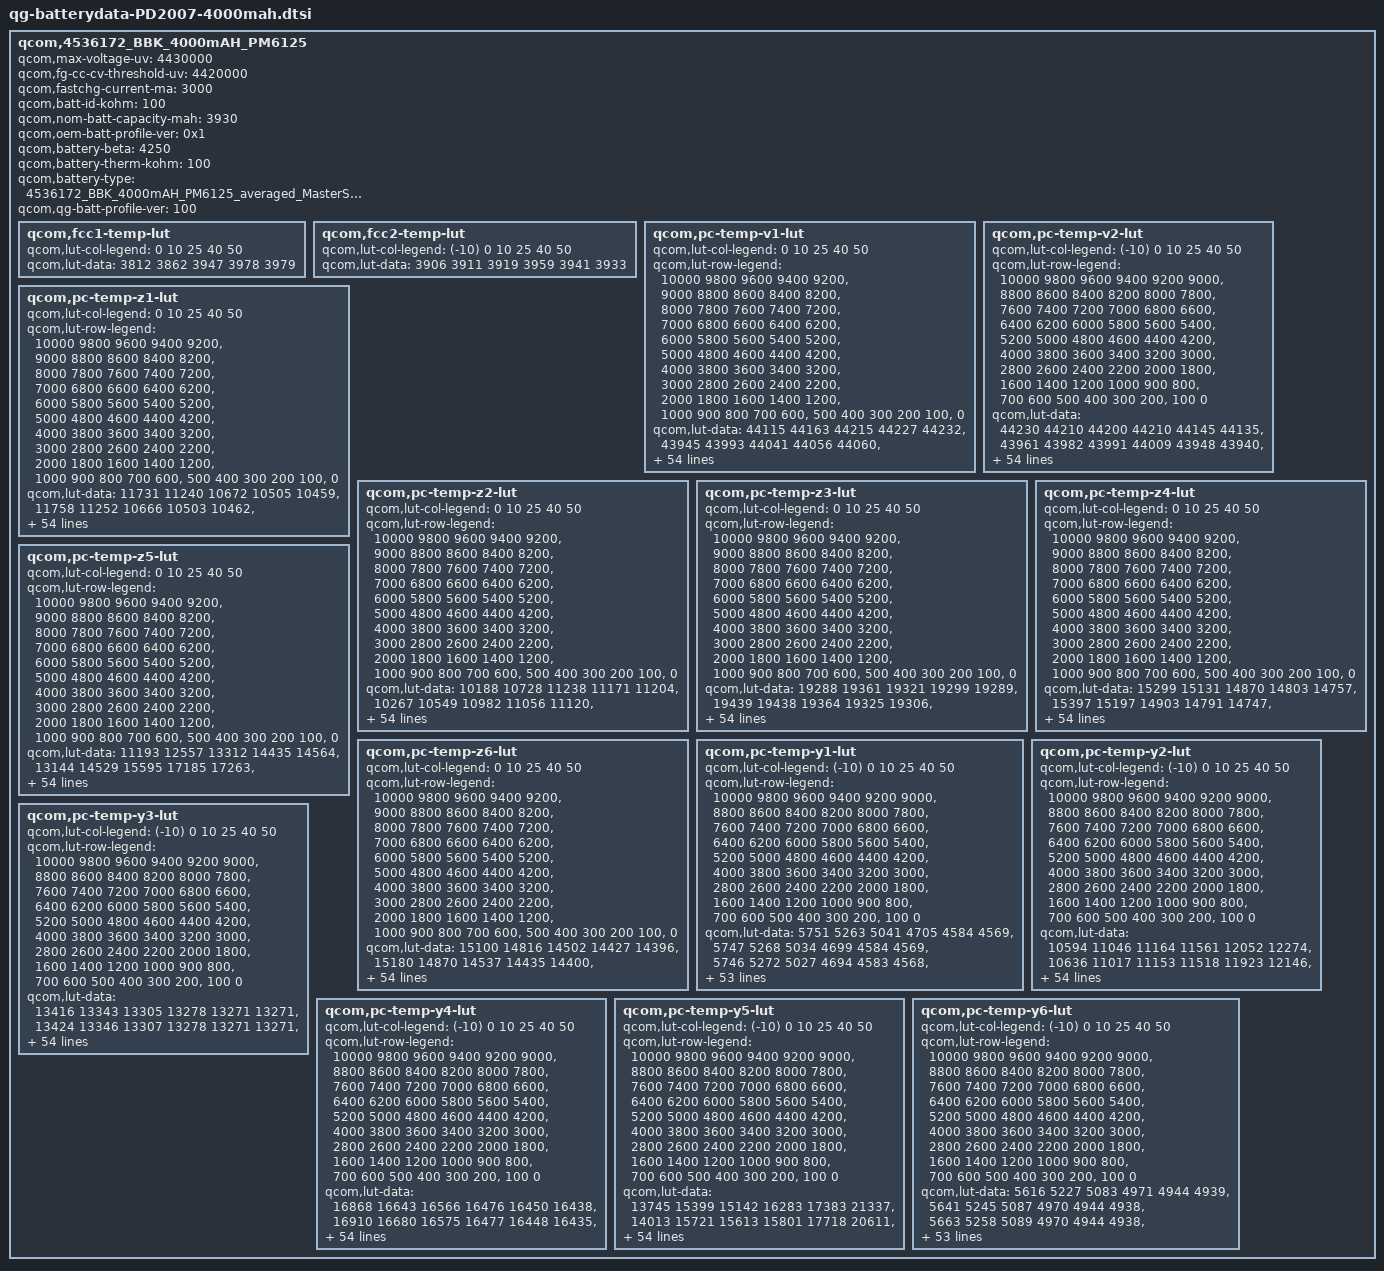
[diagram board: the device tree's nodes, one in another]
qcom,4536172_BBK_4000mAH_PM6125 {
    /* 4536172_BBK_4000mAH_PM6125_averaged_MasterSlave_Apr3th2020 */
    qcom,max-voltage-uv = <4430000>;
    qcom,fg-cc-cv-threshold-uv = <4420000>;
    qcom,fastchg-current-ma = <3000>;
    qcom,batt-id-kohm = <100>;
    qcom,nom-batt-capacity-mah = <3930>;/*min value*/
    qcom,oem-batt-profile-ver = <0x1>;
    qcom,battery-beta = <4250>;
    qcom,battery-therm-kohm = <100>;
    qcom,battery-type = "4536172_BBK_4000mAH_PM6125_averaged_MasterSlave_Apr3th2020";
    qcom,qg-batt-profile-ver = <100>;

	qcom,fcc1-temp-lut {
		qcom,lut-col-legend = <0 10 25 40 50>;
		qcom,lut-data = <3812 3862 3947 3978 3979>;
	};

	qcom,fcc2-temp-lut {
		qcom,lut-col-legend = <(-10) 0 10 25 40 50>;
		qcom,lut-data = <3906 3911 3919 3959 3941 3933>;
	};

	qcom,pc-temp-v1-lut {
		qcom,lut-col-legend = <0 10 25 40 50>;
		qcom,lut-row-legend = <10000 9800 9600 9400 9200>,
			<9000 8800 8600 8400 8200>,
			<8000 7800 7600 7400 7200>,
			<7000 6800 6600 6400 6200>,
			<6000 5800 5600 5400 5200>,
			<5000 4800 4600 4400 4200>,
			<4000 3800 3600 3400 3200>,
			<3000 2800 2600 2400 2200>,
			<2000 1800 1600 1400 1200>,
			<1000 900 800 700 600>,
			<500 400 300 200 100>,
			<0>;
		qcom,lut-data = <44115 44163 44215 44227 44232>,
			<43945 43993 44041 44056 44060>,
			<43740 43803 43855 43874 43880>,
			<43527 43601 43659 43682 43692>,
			<43306 43388 43453 43480 43496>,
			<43076 43160 43234 43267 43288>,
			<42843 42927 43000 43040 43063>,
			<42604 42690 42762 42805 42828>,
			<42366 42451 42522 42568 42593>,
			<42130 42213 42279 42325 42353>,
			<41897 41977 42040 42085 42115>,
			<41672 41745 41803 41846 41879>,
			<41451 41519 41571 41612 41646>,
			<41239 41297 41343 41383 41417>,
			<41035 41084 41122 41160 41191>,
			<40840 40881 40907 40943 40972>,
			<40644 40684 40700 40732 40758>,
			<40453 40492 40500 40528 40552>,
			<40258 40307 40317 40338 40361>,
			<40034 40104 40139 40159 40182>,
			<39768 39848 39930 39962 39985>,
			<39523 39581 39671 39719 39746>,
			<39342 39374 39426 39473 39502>,
			<39188 39205 39240 39276 39303>,
			<39054 39060 39080 39105 39128>,
			<38937 38932 38940 38956 38975>,
			<38833 38819 38815 38827 38843>,
			<38738 38715 38703 38713 38726>,
			<38649 38620 38597 38605 38614>,
			<38570 38532 38498 38505 38510>,
			<38501 38456 38409 38413 38415>,
			<38437 38386 38328 38327 38327>,
			<38383 38324 38255 38248 38247>,
			<38335 38268 38193 38178 38172>,
			<38292 38218 38139 38117 38104>,
			<38253 38174 38087 38054 38032>,
			<38218 38139 38040 37987 37950>,
			<38171 38094 37990 37913 37862>,
			<38084 38013 37916 37829 37768>,
			<37967 37899 37815 37733 37666>,
			<37844 37778 37703 37625 37553>,
			<37708 37646 37580 37498 37417>,
			<37553 37496 37442 37357 37275>,
			<37376 37318 37274 37193 37135>,
			<37232 37183 37141 37074 37016>,
			<37160 37111 37069 37014 36947>,
			<37134 37091 37049 36998 36930>,
			<37112 37071 37035 36983 36913>,
			<37082 37044 37012 36960 36883>,
			<36984 36946 36895 36797 36686>,
			<36630 36584 36531 36425 36348>,
			<36151 36108 36058 35951 35852>,
			<35536 35495 35449 35338 35236>,
			<34697 34657 34623 34503 34398>,
			<33361 33336 33337 33206 33096>,
			<30000 30000 30000 30000 30000>;
	};

	qcom,pc-temp-v2-lut {
		qcom,lut-col-legend = <(-10) 0 10 25 40 50>;
		qcom,lut-row-legend = <10000 9800 9600 9400 9200 9000>,
			<8800 8600 8400 8200 8000 7800>,
			<7600 7400 7200 7000 6800 6600>,
			<6400 6200 6000 5800 5600 5400>,
			<5200 5000 4800 4600 4400 4200>,
			<4000 3800 3600 3400 3200 3000>,
			<2800 2600 2400 2200 2000 1800>,
			<1600 1400 1200 1000 900 800>,
			<700 600 500 400 300 200>,
			<100 0>;
		qcom,lut-data = <44230 44210 44200 44210 44145 44135>,
			<43961 43982 43991 44009 43948 43940>,
			<43704 43757 43782 43805 43747 43740>,
			<43460 43538 43575 43600 43542 43536>,
			<43234 43326 43369 43393 43333 43328>,
			<43006 43110 43158 43178 43116 43112>,
			<42766 42878 42930 42948 42887 42887>,
			<42522 42637 42693 42709 42649 42654>,
			<42277 42398 42454 42468 42411 42419>,
			<42032 42158 42213 42225 42170 42179>,
			<41788 41921 41973 41984 41932 41940>,
			<41538 41687 41737 41746 41696 41705>,
			<41287 41457 41506 41513 41464 41473>,
			<41072 41233 41277 41283 41236 41246>,
			<40913 41019 41054 41058 41013 41025>,
			<40749 40808 40834 40839 40796 40809>,
			<40493 40594 40621 40628 40588 40602>,
			<40130 40382 40415 40424 40386 40401>,
			<39809 40150 40194 40221 40187 40203>,
			<39573 39873 39934 40021 39993 40011>,
			<39367 39588 39671 39812 39793 39814>,
			<39167 39355 39440 39568 39558 39582>,
			<38974 39154 39229 39301 39295 39319>,
			<38798 38977 39045 39089 39082 39103>,
			<38641 38819 38889 38929 38928 38948>,
			<38499 38678 38752 38792 38798 38817>,
			<38368 38549 38625 38664 38675 38692>,
			<38241 38432 38509 38548 38562 38577>,
			<38137 38324 38401 38442 38457 38471>,
			<38065 38220 38298 38344 38358 38370>,
			<38010 38125 38203 38254 38267 38277>,
			<37958 38038 38115 38169 38184 38192>,
			<37912 37959 38033 38090 38111 38116>,
			<37865 37889 37956 38012 38032 38033>,
			<37814 37837 37884 37939 37939 37929>,
			<37759 37795 37816 37864 37838 37813>,
			<37697 37749 37749 37779 37737 37700>,
			<37626 37699 37685 37685 37632 37588>,
			<37546 37639 37614 37591 37529 37480>,
			<37453 37557 37528 37505 37435 37383>,
			<37345 37444 37424 37416 37341 37290>,
			<37225 37313 37305 37304 37226 37174>,
			<37081 37155 37151 37171 37080 37013>,
			<36936 37000 37015 37032 36962 36898>,
			<36816 36875 36920 36924 36878 36835>,
			<36717 36793 36860 36897 36851 36794>,
			<36673 36763 36837 36883 36835 36783>,
			<36615 36722 36809 36863 36807 36760>,
			<36536 36663 36745 36815 36722 36648>,
			<36388 36492 36552 36645 36454 36357>,
			<36081 36108 36125 36238 36010 35916>,
			<35598 35568 35569 35716 35444 35352>,
			<34936 34865 34842 35025 34697 34599>,
			<33997 33908 33834 34080 33662 33581>,
			<32497 32351 32216 32691 32346 32129>,
			<29022 29007 29056 29278 29005 29003>;
	};

	qcom,pc-temp-z1-lut {
		qcom,lut-col-legend = <0 10 25 40 50>;
		qcom,lut-row-legend = <10000 9800 9600 9400 9200>,
			<9000 8800 8600 8400 8200>,
			<8000 7800 7600 7400 7200>,
			<7000 6800 6600 6400 6200>,
			<6000 5800 5600 5400 5200>,
			<5000 4800 4600 4400 4200>,
			<4000 3800 3600 3400 3200>,
			<3000 2800 2600 2400 2200>,
			<2000 1800 1600 1400 1200>,
			<1000 900 800 700 600>,
			<500 400 300 200 100>,
			<0>;
		qcom,lut-data = <11731 11240 10672 10505 10459>,
			<11758 11252 10666 10503 10462>,
			<11745 11240 10663 10500 10463>,
			<11731 11222 10661 10497 10464>,
			<11713 11213 10658 10493 10465>,
			<11695 11207 10655 10490 10465>,
			<11686 11201 10650 10490 10463>,
			<11679 11196 10645 10489 10462>,
			<11675 11191 10641 10487 10460>,
			<11674 11186 10638 10485 10456>,
			<11673 11179 10635 10484 10455>,
			<11671 11175 10632 10484 10460>,
			<11661 11173 10631 10485 10466>,
			<11651 11172 10631 10486 10465>,
			<11649 11171 10632 10488 10460>,
			<11647 11165 10633 10488 10458>,
			<11647 11158 10635 10489 10459>,
			<11648 11158 10637 10490 10461>,
			<11651 11163 10639 10491 10463>,
			<11655 11165 10640 10492 10465>,
			<11661 11166 10641 10494 10467>,
			<11666 11167 10644 10496 10468>,
			<11667 11169 10647 10498 10470>,
			<11667 11174 10651 10501 10474>,
			<11669 11180 10657 10505 10481>,
			<11677 11184 10661 10507 10484>,
			<11687 11189 10665 10509 10483>,
			<11693 11192 10669 10510 10480>,
			<11696 11199 10674 10512 10481>,
			<11699 11206 10681 10515 10484>,
			<11701 11210 10686 10518 10487>,
			<11703 11214 10690 10520 10489>,
			<11705 11218 10694 10523 10490>,
			<11710 11223 10698 10526 10491>,
			<11716 11228 10704 10530 10493>,
			<11723 11235 10709 10533 10495>,
			<11733 11244 10715 10537 10500>,
			<11743 11252 10720 10540 10506>,
			<11756 11256 10724 10543 10507>,
			<11769 11260 10728 10547 10507>,
			<11776 11265 10731 10549 10507>,
			<11781 11277 10734 10549 10507>,
			<11785 11286 10737 10549 10508>,
			<11790 11291 10741 10552 10512>,
			<11787 11297 10741 10554 10513>,
			<11801 11302 10745 10556 10511>,
			<11804 11313 10744 10556 10511>,
			<11807 11312 10749 10555 10509>,
			<11813 11314 10753 10559 10511>,
			<11825 11339 10759 10562 10527>,
			<11839 11335 10763 10567 10519>,
			<11852 11345 10772 10571 10527>,
			<11873 11361 10785 10579 10531>,
			<11904 11378 10796 10589 10539>,
			<11904 11378 10796 10589 10539>,
			<11904 11378 10796 10589 10539>;
	};

	qcom,pc-temp-z2-lut {
		qcom,lut-col-legend = <0 10 25 40 50>;
		qcom,lut-row-legend = <10000 9800 9600 9400 9200>,
			<9000 8800 8600 8400 8200>,
			<8000 7800 7600 7400 7200>,
			<7000 6800 6600 6400 6200>,
			<6000 5800 5600 5400 5200>,
			<5000 4800 4600 4400 4200>,
			<4000 3800 3600 3400 3200>,
			<3000 2800 2600 2400 2200>,
			<2000 1800 1600 1400 1200>,
			<1000 900 800 700 600>,
			<500 400 300 200 100>,
			<0>;
		qcom,lut-data = <10188 10728 11238 11171 11204>,
			<10267 10549 10982 11056 11120>,
			<10359 10525 10870 10983 11069>,
			<10392 10514 10863 10961 11065>,
			<10385 10515 10865 10953 11065>,
			<10380 10526 10861 10951 11062>,
			<10376 10532 10846 10926 11032>,
			<10372 10531 10836 10903 11001>,
			<10370 10529 10845 10903 11030>,
			<10371 10526 10857 10906 11126>,
			<10373 10516 10850 10914 11173>,
			<10375 10506 10806 10950 11135>,
			<10380 10505 10778 10990 11089>,
			<10384 10508 10787 10994 11088>,
			<10386 10507 10804 10975 11095>,
			<10388 10499 10808 10967 11103>,
			<10388 10490 10800 10975 11129>,
			<10379 10485 10793 10981 11155>,
			<10363 10482 10775 10969 11145>,
			<10343 10480 10743 10940 11096>,
			<10312 10489 10739 10907 11043>,
			<10291 10502 10773 10859 10941>,
			<10297 10498 10800 10813 10835>,
			<10311 10462 10784 10802 10815>,
			<10316 10435 10748 10825 10828>,
			<10308 10436 10737 10838 10856>,
			<10298 10439 10751 10874 10918>,
			<10299 10444 10768 10918 10987>,
			<10311 10454 10779 10916 11018>,
			<10324 10466 10790 10890 11036>,
			<10335 10483 10803 10876 11050>,
			<10345 10505 10818 10901 11062>,
			<10350 10514 10835 10944 11080>,
			<10350 10514 10859 10983 11123>,
			<10351 10512 10890 11030 11200>,
			<10355 10512 10911 11082 11247>,
			<10362 10513 10919 11164 11258>,
			<10372 10516 10928 11239 11269>,
			<10393 10549 10964 11237 11292>,
			<10415 10605 11045 11180 11322>,
			<10418 10618 11082 11143 11336>,
			<10415 10590 11021 11164 11280>,
			<10413 10581 10977 11186 11228>,
			<10415 10610 11038 11174 11229>,
			<10437 10603 11064 11127 11210>,
			<10472 10612 11023 11120 11213>,
			<10487 10637 11006 11081 11273>,
			<10505 10629 10961 11107 11298>,
			<11407 10650 10968 11228 11300>,
			<13406 10731 11246 11013 11037>,
			<10457 10801 11090 10885 10724>,
			<10329 10826 10977 10778 10849>,
			<10148 10840 10872 10765 10793>,
			<9941 10616 10893 10742 10762>,
			<9941 10616 10893 10742 10762>,
			<9941 10616 10893 10742 10762>;
	};

	qcom,pc-temp-z3-lut {
		qcom,lut-col-legend = <0 10 25 40 50>;
		qcom,lut-row-legend = <10000 9800 9600 9400 9200>,
			<9000 8800 8600 8400 8200>,
			<8000 7800 7600 7400 7200>,
			<7000 6800 6600 6400 6200>,
			<6000 5800 5600 5400 5200>,
			<5000 4800 4600 4400 4200>,
			<4000 3800 3600 3400 3200>,
			<3000 2800 2600 2400 2200>,
			<2000 1800 1600 1400 1200>,
			<1000 900 800 700 600>,
			<500 400 300 200 100>,
			<0>;
		qcom,lut-data = <19288 19361 19321 19299 19289>,
			<19439 19438 19364 19325 19306>,
			<19563 19484 19382 19340 19316>,
			<19611 19512 19381 19340 19318>,
			<19616 19514 19380 19337 19318>,
			<19618 19509 19379 19336 19318>,
			<19615 19502 19376 19333 19319>,
			<19606 19494 19374 19330 19319>,
			<19600 19485 19370 19329 19317>,
			<19598 19481 19366 19329 19311>,
			<19596 19479 19363 19328 19309>,
			<19594 19478 19358 19327 19311>,
			<19586 19477 19355 19326 19313>,
			<19578 19477 19352 19322 19313>,
			<19576 19477 19349 19315 19309>,
			<19576 19476 19350 19312 19307>,
			<19577 19475 19353 19312 19305>,
			<19577 19476 19356 19313 19303>,
			<19577 19477 19355 19312 19303>,
			<19581 19480 19354 19312 19304>,
			<19600 19489 19356 19312 19306>,
			<19618 19503 19376 19322 19311>,
			<19626 19513 19393 19335 19316>,
			<19633 19521 19392 19338 19322>,
			<19634 19526 19389 19337 19330>,
			<19632 19522 19387 19337 19334>,
			<19628 19513 19384 19337 19330>,
			<19624 19506 19382 19338 19323>,
			<19617 19500 19380 19337 19320>,
			<19611 19495 19379 19332 19316>,
			<19606 19491 19377 19329 19314>,
			<19601 19486 19375 19327 19311>,
			<19596 19483 19373 19326 19308>,
			<19590 19481 19371 19324 19306>,
			<19585 19479 19370 19323 19304>,
			<19583 19479 19368 19321 19303>,
			<19583 19477 19367 19320 19306>,
			<19581 19476 19365 19318 19310>,
			<19575 19471 19362 19318 19310>,
			<19568 19464 19358 19318 19306>,
			<19564 19461 19355 19318 19304>,
			<19562 19459 19352 19323 19307>,
			<19559 19458 19350 19328 19310>,
			<19548 19456 19348 19329 19308>,
			<19532 19437 19346 19326 19305>,
			<19488 19429 19345 19316 19307>,
			<19476 19414 19345 19309 19300>,
			<19462 19411 19336 19310 19297>,
			<19437 19406 19330 19306 19300>,
			<19369 19395 19321 19326 19326>,
			<19395 19388 19326 19330 19327>,
			<19343 19360 19330 19328 19321>,
			<19308 19338 19339 19328 19321>,
			<19312 19371 19341 19333 19322>,
			<19312 19371 19341 19333 19322>,
			<19312 19371 19341 19333 19322>;
	};

	qcom,pc-temp-z4-lut {
		qcom,lut-col-legend = <0 10 25 40 50>;
		qcom,lut-row-legend = <10000 9800 9600 9400 9200>,
			<9000 8800 8600 8400 8200>,
			<8000 7800 7600 7400 7200>,
			<7000 6800 6600 6400 6200>,
			<6000 5800 5600 5400 5200>,
			<5000 4800 4600 4400 4200>,
			<4000 3800 3600 3400 3200>,
			<3000 2800 2600 2400 2200>,
			<2000 1800 1600 1400 1200>,
			<1000 900 800 700 600>,
			<500 400 300 200 100>,
			<0>;
		qcom,lut-data = <15299 15131 14870 14803 14757>,
			<15397 15197 14903 14791 14747>,
			<15340 15134 14911 14779 14739>,
			<15271 15042 14879 14769 14731>,
			<15162 14986 14832 14758 14724>,
			<15055 14944 14810 14750 14719>,
			<15015 14915 14799 14743 14714>,
			<14995 14899 14789 14736 14709>,
			<14979 14887 14779 14730 14704>,
			<14961 14875 14770 14724 14698>,
			<14944 14862 14763 14717 14695>,
			<14932 14851 14756 14710 14695>,
			<14922 14840 14750 14704 14694>,
			<14914 14830 14744 14700 14691>,
			<14906 14824 14738 14697 14681>,
			<14898 14820 14730 14693 14673>,
			<14895 14818 14720 14685 14666>,
			<14902 14817 14713 14677 14660>,
			<14919 14816 14714 14676 14656>,
			<14961 14817 14715 14676 14653>,
			<15100 14910 14726 14678 14652>,
			<15204 15046 14790 14708 14676>,
			<15188 15065 14842 14744 14706>,
			<15141 15007 14838 14751 14714>,
			<15097 14950 14825 14753 14718>,
			<15052 14923 14812 14753 14720>,
			<15014 14904 14798 14745 14714>,
			<15002 14893 14784 14733 14706>,
			<14996 14887 14773 14726 14702>,
			<14993 14883 14764 14720 14700>,
			<14995 14881 14758 14715 14697>,
			<14998 14880 14755 14709 14692>,
			<14999 14880 14753 14703 14685>,
			<14998 14884 14753 14700 14680>,
			<14996 14889 14755 14698 14674>,
			<14990 14888 14757 14697 14671>,
			<14979 14880 14766 14710 14682>,
			<14969 14872 14775 14727 14697>,
			<14963 14869 14775 14729 14697>,
			<14958 14867 14774 14723 14689>,
			<14945 14861 14772 14716 14683>,
			<14914 14836 14760 14706 14684>,
			<14892 14818 14750 14700 14684>,
			<14879 14810 14748 14703 14668>,
			<14822 14782 14740 14702 14671>,
			<14812 14751 14720 14696 14669>,
			<14806 14741 14702 14686 14662>,
			<14807 14728 14686 14668 14650>,
			<14823 14723 14680 14662 14648>,
			<14895 14742 14702 14660 14697>,
			<14886 14758 14699 14658 14617>,
			<14943 14787 14694 14659 14643>,
			<14989 14813 14685 14659 14642>,
			<15000 14784 14683 14655 14641>,
			<15000 14784 14683 14655 14641>,
			<15000 14784 14683 14655 14641>;
	};

	qcom,pc-temp-z5-lut {
		qcom,lut-col-legend = <0 10 25 40 50>;
		qcom,lut-row-legend = <10000 9800 9600 9400 9200>,
			<9000 8800 8600 8400 8200>,
			<8000 7800 7600 7400 7200>,
			<7000 6800 6600 6400 6200>,
			<6000 5800 5600 5400 5200>,
			<5000 4800 4600 4400 4200>,
			<4000 3800 3600 3400 3200>,
			<3000 2800 2600 2400 2200>,
			<2000 1800 1600 1400 1200>,
			<1000 900 800 700 600>,
			<500 400 300 200 100>,
			<0>;
		qcom,lut-data = <11193 12557 13312 14435 14564>,
			<13144 14529 15595 17185 17263>,
			<14921 16034 16911 18899 18973>,
			<16250 17168 17512 19260 19356>,
			<17329 17783 17867 19314 19528>,
			<18056 18224 17959 19273 19663>,
			<18155 18404 17957 18919 20129>,
			<18148 18197 17943 18590 20601>,
			<18152 17860 17813 18695 20441>,
			<18457 17799 17632 18985 19691>,
			<18980 17992 17551 19225 19332>,
			<19121 18263 17280 19395 19463>,
			<18965 18561 17009 19448 19666>,
			<18813 18940 16881 18954 19748>,
			<18966 19294 16874 17705 19691>,
			<19459 19707 17138 17184 19673>,
			<19709 20030 18076 17618 19838>,
			<19335 20097 18737 18123 20090>,
			<18811 20123 18741 18201 20325>,
			<19050 20128 18716 18187 20583>,
			<21149 19433 18593 18105 20549>,
			<22828 18414 17895 17440 18880>,
			<21738 18209 17220 16656 16957>,
			<19205 18368 16961 16438 16944>,
			<18243 18589 16769 16328 17719>,
			<18961 18980 16757 16371 18138>,
			<20058 19668 17220 16985 18151>,
			<20958 20343 17917 17783 18164>,
			<21868 21039 18661 18130 18213>,
			<22485 21691 19574 18349 18308>,
			<22864 22201 20468 18612 18348>,
			<23197 22643 21362 19298 18509>,
			<23250 22944 22195 20226 18847>,
			<22991 23211 22961 20997 19297>,
			<22736 23422 23699 21755 20000>,
			<22710 23444 23931 22069 20655>,
			<22750 23394 23400 21064 21263>,
			<22847 23336 22625 19700 21728>,
			<23098 23295 22030 19499 21472>,
			<23360 23260 21352 19566 20084>,
			<23337 23172 20929 19695 19271>,
			<22897 22732 20239 21115 20031>,
			<22270 22493 19788 22310 20703>,
			<21246 22264 18885 21884 19600>,
			<21337 20806 18695 20257 18302>,
			<17435 20346 19397 18553 19178>,
			<16664 18442 20896 18409 18913>,
			<15755 18499 20252 20762 21063>,
			<15295 17981 19605 21039 23353>,
			<13600 16457 15850 22845 27708>,
			<13569 15335 15892 24236 55604>,
			<12394 13735 16122 22669 28724>,
			<11574 12896 17240 22700 28301>,
			<11505 13893 17536 24695 28093>,
			<11505 13893 17536 24695 28093>,
			<11505 13893 17536 24695 28093>;
	};

	qcom,pc-temp-z6-lut {
		qcom,lut-col-legend = <0 10 25 40 50>;
		qcom,lut-row-legend = <10000 9800 9600 9400 9200>,
			<9000 8800 8600 8400 8200>,
			<8000 7800 7600 7400 7200>,
			<7000 6800 6600 6400 6200>,
			<6000 5800 5600 5400 5200>,
			<5000 4800 4600 4400 4200>,
			<4000 3800 3600 3400 3200>,
			<3000 2800 2600 2400 2200>,
			<2000 1800 1600 1400 1200>,
			<1000 900 800 700 600>,
			<500 400 300 200 100>,
			<0>;
		qcom,lut-data = <15100 14816 14502 14427 14396>,
			<15180 14870 14537 14435 14400>,
			<15183 14851 14549 14439 14403>,
			<15179 14819 14534 14436 14402>,
			<15123 14793 14512 14429 14399>,
			<15048 14766 14501 14423 14396>,
			<15014 14744 14494 14418 14394>,
			<14995 14729 14487 14414 14392>,
			<14980 14717 14481 14410 14387>,
			<14967 14707 14474 14407 14382>,
			<14955 14698 14468 14404 14379>,
			<14944 14691 14463 14401 14381>,
			<14933 14684 14458 14397 14383>,
			<14925 14679 14454 14393 14381>,
			<14919 14675 14450 14389 14376>,
			<14915 14672 14447 14385 14370>,
			<14913 14671 14445 14382 14366>,
			<14916 14670 14443 14379 14362>,
			<14922 14671 14444 14379 14361>,
			<14943 14672 14444 14379 14361>,
			<15015 14720 14450 14380 14361>,
			<15070 14787 14489 14400 14374>,
			<15066 14799 14522 14423 14391>,
			<15054 14781 14520 14427 14400>,
			<15042 14761 14514 14428 14407>,
			<15025 14748 14507 14429 14409>,
			<15009 14738 14501 14426 14404>,
			<15004 14732 14494 14422 14397>,
			<15001 14728 14490 14418 14394>,
			<15000 14726 14486 14413 14392>,
			<15001 14725 14483 14409 14389>,
			<15002 14724 14481 14406 14385>,
			<15004 14724 14480 14403 14381>,
			<15004 14727 14480 14401 14377>,
			<15005 14731 14481 14400 14373>,
			<15005 14732 14482 14399 14372>,
			<15008 14732 14486 14404 14378>,
			<15010 14732 14490 14412 14387>,
			<15012 14732 14490 14412 14387>,
			<15015 14732 14488 14410 14382>,
			<15014 14730 14486 14408 14379>,
			<15009 14723 14480 14407 14381>,
			<15007 14719 14475 14406 14383>,
			<15006 14719 14474 14408 14375>,
			<14990 14703 14471 14407 14376>,
			<14968 14689 14462 14399 14376>,
			<14963 14679 14455 14391 14369>,
			<14962 14675 14444 14384 14362>,
			<14964 14674 14439 14380 14362>,
			<14971 14682 14445 14390 14401>,
			<14989 14691 14448 14392 14365>,
			<14999 14695 14450 14393 14375>,
			<15015 14703 14453 14394 14376>,
			<15045 14719 14457 14398 14378>,
			<15045 14719 14457 14398 14378>,
			<15045 14719 14457 14398 14378>;
	};

	qcom,pc-temp-y1-lut {
		qcom,lut-col-legend = <(-10) 0 10 25 40 50>;
		qcom,lut-row-legend = <10000 9800 9600 9400 9200 9000>,
			<8800 8600 8400 8200 8000 7800>,
			<7600 7400 7200 7000 6800 6600>,
			<6400 6200 6000 5800 5600 5400>,
			<5200 5000 4800 4600 4400 4200>,
			<4000 3800 3600 3400 3200 3000>,
			<2800 2600 2400 2200 2000 1800>,
			<1600 1400 1200 1000 900 800>,
			<700 600 500 400 300 200>,
			<100 0>;
		qcom,lut-data = <5751 5263 5041 4705 4584 4569>,
			<5747 5268 5034 4699 4584 4569>,
			<5746 5272 5027 4694 4583 4568>,
			<5747 5275 5020 4689 4583 4568>,
			<5748 5277 5014 4685 4582 4567>,
			<5748 5278 5009 4681 4581 4566>,
			<5749 5278 5005 4679 4579 4564>,
			<5751 5277 5003 4676 4578 4561>,
			<5752 5276 4999 4673 4578 4561>,
			<5756 5273 4994 4670 4578 4563>,
			<5760 5270 4990 4667 4578 4564>,
			<5761 5267 4988 4664 4577 4564>,
			<5762 5263 4987 4662 4576 4563>,
			<5762 5261 4985 4661 4576 4562>,
			<5759 5263 4983 4661 4576 4562>,
			<5756 5265 4981 4661 4576 4562>,
			<5757 5269 4981 4661 4577 4562>,
			<5762 5274 4982 4662 4577 4561>,
			<5765 5276 4982 4663 4577 4562>,
			<5767 5276 4982 4663 4577 4565>,
			<5769 5275 4982 4664 4576 4568>,
			<5769 5276 4983 4666 4577 4568>,
			<5770 5280 4984 4670 4580 4566>,
			<5770 5282 4986 4672 4582 4565>,
			<5772 5282 4988 4674 4582 4566>,
			<5775 5281 4991 4676 4582 4568>,
			<5775 5281 4992 4678 4583 4570>,
			<5773 5281 4993 4681 4584 4572>,
			<5771 5281 4994 4683 4586 4574>,
			<5772 5280 4997 4684 4587 4574>,
			<5775 5279 4999 4685 4589 4574>,
			<5776 5279 5003 4687 4591 4574>,
			<5772 5287 5008 4692 4592 4574>,
			<5769 5294 5012 4695 4593 4574>,
			<5769 5295 5013 4698 4593 4575>,
			<5769 5295 5014 4701 4594 4577>,
			<5771 5294 5015 4703 4595 4578>,
			<5776 5292 5018 4707 4598 4582>,
			<5782 5291 5021 4709 4601 4585>,
			<5782 5293 5023 4711 4602 4587>,
			<5778 5303 5025 4712 4604 4588>,
			<5775 5310 5027 4714 4605 4588>,
			<5770 5313 5032 4716 4606 4586>,
			<5767 5316 5038 4720 4608 4586>,
			<5780 5321 5048 4724 4610 4590>,
			<5793 5320 5054 4726 4610 4587>,
			<5800 5318 5056 4728 4608 4587>,
			<5825 5334 5060 4728 4609 4591>,
			<5817 5333 5065 4729 4610 4592>,
			<5852 5337 5069 4732 4614 4590>,
			<5860 5339 5069 4734 4616 4592>,
			<5888 5346 5091 4737 4618 4598>,
			<5972 5364 5102 4749 4623 4604>,
			<6010 5399 5119 4754 4633 4607>,
			<6010 5399 5119 4754 4633 4607>,
			<6010 5399 5119 4754 4633 4607>;
	};

	qcom,pc-temp-y2-lut {
		qcom,lut-col-legend = <(-10) 0 10 25 40 50>;
		qcom,lut-row-legend = <10000 9800 9600 9400 9200 9000>,
			<8800 8600 8400 8200 8000 7800>,
			<7600 7400 7200 7000 6800 6600>,
			<6400 6200 6000 5800 5600 5400>,
			<5200 5000 4800 4600 4400 4200>,
			<4000 3800 3600 3400 3200 3000>,
			<2800 2600 2400 2200 2000 1800>,
			<1600 1400 1200 1000 900 800>,
			<700 600 500 400 300 200>,
			<100 0>;
		qcom,lut-data = <10594 11046 11164 11561 12052 12274>,
			<10636 11017 11153 11518 11923 12146>,
			<10672 10989 11139 11470 11793 11980>,
			<10702 10963 11124 11424 11670 11812>,
			<10721 10939 11108 11390 11564 11673>,
			<10730 10920 11090 11375 11485 11599>,
			<10722 10902 11069 11382 11428 11589>,
			<10707 10887 11046 11395 11385 11592>,
			<10702 10880 11029 11397 11374 11571>,
			<10710 10877 11011 11390 11404 11478>,
			<10721 10878 10999 11378 11428 11405>,
			<10734 10883 11003 11337 11412 11423>,
			<10752 10892 11015 11276 11389 11472>,
			<10781 10907 11032 11263 11384 11500>,
			<10875 10938 11059 11293 11412 11526>,
			<10966 10980 11094 11332 11441 11550>,
			<10965 11029 11143 11364 11446 11545>,
			<10923 11088 11208 11399 11447 11516>,
			<10894 11113 11234 11447 11461 11512>,
			<10885 11069 11211 11533 11540 11564>,
			<10878 11011 11181 11595 11620 11639>,
			<10876 11012 11185 11595 11633 11705>,
			<10876 11058 11220 11589 11633 11774>,
			<10877 11099 11254 11577 11642 11827>,
			<10875 11120 11275 11537 11695 11871>,
			<10869 11138 11294 11501 11763 11906>,
			<10801 11150 11311 11525 11799 11931>,
			<10371 11159 11329 11600 11823 11962>,
			<9973 11166 11338 11653 11848 11991>,
			<9866 11178 11335 11681 11874 12040>,
			<9790 11194 11327 11702 11904 12102>,
			<9750 11201 11322 11712 11951 12147>,
			<9728 11207 11327 11709 12024 12202>,
			<9712 11212 11333 11706 12079 12233>,
			<9699 11096 11337 11690 12111 12190>,
			<9687 10798 11345 11673 12130 12115>,
			<9679 10669 11351 11684 12090 12100>,
			<9673 10792 11342 11713 11924 12123>,
			<9669 10923 11325 11727 11810 12142>,
			<9666 10887 11305 11717 11889 12114>,
			<9662 10781 11273 11704 12026 12046>,
			<9660 10646 11228 11720 12025 11992>,
			<9659 10427 11148 11780 11873 11938>,
			<9658 10198 11043 11740 11839 11894>,
			<9657 9904 10907 11624 11899 11859>,
			<9656 9747 10794 11641 11776 11721>,
			<9655 9720 10767 11592 11747 11617>,
			<9654 9713 10796 11587 11670 11600>,
			<9654 9694 10734 11590 11476 11592>,
			<9653 9681 10648 11545 11527 11540>,
			<9652 9670 10517 11536 11474 11494>,
			<9651 9661 10395 11357 11418 11477>,
			<9650 9656 10241 11314 11318 11365>,
			<9652 9654 10055 11160 11172 11183>,
			<9652 9654 10055 11160 11172 11183>,
			<9652 9654 10055 11160 11172 11183>;
	};

	qcom,pc-temp-y3-lut {
		qcom,lut-col-legend = <(-10) 0 10 25 40 50>;
		qcom,lut-row-legend = <10000 9800 9600 9400 9200 9000>,
			<8800 8600 8400 8200 8000 7800>,
			<7600 7400 7200 7000 6800 6600>,
			<6400 6200 6000 5800 5600 5400>,
			<5200 5000 4800 4600 4400 4200>,
			<4000 3800 3600 3400 3200 3000>,
			<2800 2600 2400 2200 2000 1800>,
			<1600 1400 1200 1000 900 800>,
			<700 600 500 400 300 200>,
			<100 0>;
		qcom,lut-data = <13416 13343 13305 13278 13271 13271>,
			<13424 13346 13307 13278 13271 13271>,
			<13433 13349 13310 13278 13271 13271>,
			<13442 13353 13313 13278 13272 13271>,
			<13450 13357 13317 13279 13273 13271>,
			<13456 13360 13319 13279 13273 13272>,
			<13459 13361 13320 13279 13274 13272>,
			<13461 13363 13321 13279 13275 13273>,
			<13463 13364 13321 13279 13275 13274>,
			<13465 13366 13321 13279 13276 13274>,
			<13466 13368 13321 13280 13276 13274>,
			<13466 13369 13322 13282 13276 13274>,
			<13464 13370 13325 13285 13276 13274>,
			<13460 13370 13326 13286 13276 13274>,
			<13449 13368 13326 13287 13275 13274>,
			<13436 13366 13325 13287 13274 13275>,
			<13428 13364 13326 13289 13275 13274>,
			<13421 13361 13327 13292 13276 13273>,
			<13413 13358 13326 13294 13278 13273>,
			<13403 13350 13322 13295 13281 13276>,
			<13393 13342 13315 13295 13283 13280>,
			<13385 13337 13311 13293 13282 13278>,
			<13380 13333 13309 13287 13276 13273>,
			<13375 13330 13307 13282 13272 13270>,
			<13372 13328 13306 13280 13272 13270>,
			<13368 13326 13305 13278 13272 13269>,
			<13358 13325 13305 13277 13272 13269>,
			<13325 13325 13305 13277 13272 13269>,
			<13299 13324 13305 13277 13271 13269>,
			<13301 13323 13304 13278 13271 13270>,
			<13308 13320 13304 13280 13270 13270>,
			<13318 13318 13303 13280 13271 13270>,
			<13335 13316 13302 13280 13271 13269>,
			<13357 13314 13301 13280 13272 13268>,
			<13376 13312 13300 13280 13271 13268>,
			<13396 13311 13299 13280 13270 13268>,
			<13421 13311 13298 13279 13270 13268>,
			<13458 13320 13298 13277 13270 13269>,
			<13507 13330 13297 13276 13270 13269>,
			<13569 13336 13297 13276 13271 13269>,
			<13651 13341 13298 13277 13271 13269>,
			<13750 13346 13300 13277 13271 13269>,
			<13871 13350 13303 13275 13271 13270>,
			<14026 13355 13307 13276 13271 13271>,
			<14233 13375 13314 13278 13272 13270>,
			<14515 13417 13323 13276 13272 13273>,
			<14676 13443 13327 13278 13274 13273>,
			<14785 13452 13330 13282 13275 13273>,
			<15011 13500 13337 13286 13276 13273>,
			<15344 13545 13341 13284 13276 13274>,
			<15786 13625 13347 13282 13277 13274>,
			<16898 13818 13364 13287 13277 13274>,
			<19420 14275 13397 13287 13277 13274>,
			<25190 15919 13503 13291 13279 13271>,
			<25190 15919 13503 13291 13279 13271>,
			<25190 15919 13503 13291 13279 13271>;
	};

	qcom,pc-temp-y4-lut {
		qcom,lut-col-legend = <(-10) 0 10 25 40 50>;
		qcom,lut-row-legend = <10000 9800 9600 9400 9200 9000>,
			<8800 8600 8400 8200 8000 7800>,
			<7600 7400 7200 7000 6800 6600>,
			<6400 6200 6000 5800 5600 5400>,
			<5200 5000 4800 4600 4400 4200>,
			<4000 3800 3600 3400 3200 3000>,
			<2800 2600 2400 2200 2000 1800>,
			<1600 1400 1200 1000 900 800>,
			<700 600 500 400 300 200>,
			<100 0>;
		qcom,lut-data = <16868 16643 16566 16476 16450 16438>,
			<16910 16680 16575 16477 16448 16435>,
			<17002 16725 16585 16478 16446 16434>,
			<17113 16768 16594 16479 16446 16433>,
			<17208 16802 16600 16480 16445 16433>,
			<17254 16818 16603 16482 16445 16434>,
			<17255 16812 16601 16484 16446 16436>,
			<17254 16802 16598 16486 16447 16439>,
			<17253 16798 16598 16489 16448 16441>,
			<17251 16798 16602 16494 16450 16441>,
			<17250 16799 16608 16498 16453 16442>,
			<17252 16806 16616 16501 16456 16443>,
			<17261 16828 16629 16504 16461 16446>,
			<17283 16858 16645 16509 16466 16449>,
			<17468 16905 16671 16518 16474 16453>,
			<17670 16962 16705 16530 16484 16458>,
			<17607 17020 16756 16545 16492 16465>,
			<17295 17083 16828 16563 16501 16478>,
			<17080 17108 16857 16589 16515 16492>,
			<17022 16992 16802 16640 16546 16516>,
			<16982 16818 16716 16677 16572 16536>,
			<16931 16734 16651 16636 16553 16523>,
			<16872 16684 16591 16533 16488 16471>,
			<16819 16653 16558 16489 16457 16445>,
			<16769 16635 16548 16481 16454 16445>,
			<16728 16623 16542 16477 16453 16445>,
			<16719 16615 16542 16478 16454 16446>,
			<16730 16609 16542 16481 16457 16449>,
			<16742 16604 16544 16484 16461 16451>,
			<16749 16598 16546 16490 16466 16454>,
			<16759 16591 16549 16497 16472 16457>,
			<16771 16582 16551 16504 16479 16462>,
			<16782 16568 16553 16513 16490 16473>,
			<16796 16557 16555 16517 16495 16480>,
			<16815 16568 16551 16516 16487 16474>,
			<16839 16599 16541 16515 16473 16463>,
			<16861 16620 16533 16507 16465 16454>,
			<16879 16634 16525 16482 16459 16445>,
			<16896 16648 16519 16468 16456 16440>,
			<16909 16660 16520 16464 16453 16441>,
			<16921 16673 16525 16463 16452 16444>,
			<16929 16687 16531 16464 16450 16445>,
			<16932 16703 16548 16468 16449 16444>,
			<16939 16725 16570 16466 16447 16443>,
			<16986 16763 16597 16458 16442 16437>,
			<17111 16847 16653 16481 16456 16444>,
			<17195 16894 16676 16487 16458 16463>,
			<17206 16906 16686 16496 16467 16473>,
			<17319 16984 16724 16501 16473 16455>,
			<17439 17033 16727 16492 16452 16442>,
			<17482 17042 16718 16478 16449 16456>,
			<17869 17132 16778 16497 16462 16459>,
			<19574 17320 16867 16518 16485 16467>,
			<27485 18334 17047 16591 16616 16624>,
			<27485 18334 17047 16591 16616 16624>,
			<27485 18334 17047 16591 16616 16624>;
	};

	qcom,pc-temp-y5-lut {
		qcom,lut-col-legend = <(-10) 0 10 25 40 50>;
		qcom,lut-row-legend = <10000 9800 9600 9400 9200 9000>,
			<8800 8600 8400 8200 8000 7800>,
			<7600 7400 7200 7000 6800 6600>,
			<6400 6200 6000 5800 5600 5400>,
			<5200 5000 4800 4600 4400 4200>,
			<4000 3800 3600 3400 3200 3000>,
			<2800 2600 2400 2200 2000 1800>,
			<1600 1400 1200 1000 900 800>,
			<700 600 500 400 300 200>,
			<100 0>;
		qcom,lut-data = <13745 15399 15142 16283 17383 21337>,
			<14013 15721 15613 15801 17718 20611>,
			<14347 15873 15923 15338 17870 20199>,
			<14688 15908 16100 14906 17887 20027>,
			<14979 15879 16172 14514 17819 20019>,
			<15161 15839 16165 14176 17712 20100>,
			<15244 15728 16052 13881 17533 20875>,
			<15300 15525 15827 13625 17256 22202>,
			<15293 15419 15566 13420 16968 22329>,
			<15047 15264 15086 13221 16633 20245>,
			<14701 15055 14645 13114 16253 18211>,
			<14309 14765 14441 13344 15835 17684>,
			<13802 14314 14261 13790 15365 17377>,
			<13628 13925 14093 13886 14833 17003>,
			<13982 13559 13763 13648 14075 16530>,
			<14510 13308 13480 13448 13550 16002>,
			<15015 13600 13536 13520 13581 15243>,
			<15753 14730 13856 13767 13778 14257>,
			<16179 15611 14298 14145 14098 13949>,
			<16186 16065 15249 15018 15109 15193>,
			<16113 16374 16326 16036 16210 16819>,
			<16116 16475 16836 16957 16736 17579>,
			<16164 16530 17142 17851 17177 18110>,
			<16215 16556 17366 18059 17331 18394>,
			<16257 16540 17552 17193 17542 18299>,
			<16267 16509 17705 16213 17759 18028>,
			<15884 16542 17855 15865 17622 17740>,
			<13388 16782 18128 15631 17241 17151>,
			<11286 17011 18297 15602 16835 16795>,
			<11120 16943 18236 16432 16346 17056>,
			<11057 16670 18104 17365 15934 17459>,
			<11057 16487 17999 17516 16002 17335>,
			<11258 15987 17867 17519 16536 16443>,
			<11514 15500 17780 17574 16904 15838>,
			<11648 15209 17754 17823 16966 16193>,
			<11745 14708 17686 18063 17016 16944>,
			<11847 14566 17595 17933 17179 17548>,
			<11995 15403 17309 17383 17676 18251>,
			<12114 16288 16927 17055 18142 18684>,
			<12115 16289 16551 17427 18510 18434>,
			<12048 16101 16121 17913 18863 17899>,
			<11950 15802 15849 17387 18818 18056>,
			<11710 14860 15608 15723 18119 21164>,
			<11494 14038 15496 16336 18267 22223>,
			<11440 13168 15532 18178 20071 19563>,
			<11404 12733 14912 15178 16768 20520>,
			<11395 12573 14651 15177 17439 20844>,
			<11454 12419 15075 16157 17307 18989>,
			<11502 12560 14834 17202 17710 19625>,
			<11622 12216 14968 16934 21632 24754>,
			<11495 11861 15082 17104 23519 23870>,
			<10688 11519 14661 20109 21885 21122>,
			<9706 11155 14120 18256 19793 20933>,
			<9075 10152 13718 17704 18750 18341>,
			<9075 10152 13718 17704 18750 18341>,
			<9075 10152 13718 17704 18750 18341>;
	};

	qcom,pc-temp-y6-lut {
		qcom,lut-col-legend = <(-10) 0 10 25 40 50>;
		qcom,lut-row-legend = <10000 9800 9600 9400 9200 9000>,
			<8800 8600 8400 8200 8000 7800>,
			<7600 7400 7200 7000 6800 6600>,
			<6400 6200 6000 5800 5600 5400>,
			<5200 5000 4800 4600 4400 4200>,
			<4000 3800 3600 3400 3200 3000>,
			<2800 2600 2400 2200 2000 1800>,
			<1600 1400 1200 1000 900 800>,
			<700 600 500 400 300 200>,
			<100 0>;
		qcom,lut-data = <5616 5227 5083 4971 4944 4939>,
			<5641 5245 5087 4970 4944 4938>,
			<5663 5258 5089 4970 4944 4938>,
			<5682 5267 5091 4970 4944 4938>,
			<5695 5272 5093 4970 4944 4938>,
			<5701 5273 5093 4971 4945 4939>,
			<5697 5270 5092 4971 4945 4940>,
			<5690 5263 5089 4971 4946 4941>,
			<5684 5259 5088 4972 4947 4942>,
			<5679 5257 5088 4973 4948 4942>,
			<5675 5256 5088 4974 4949 4943>,
			<5672 5257 5090 4976 4950 4943>,
			<5668 5261 5094 4979 4951 4944>,
			<5669 5267 5098 4982 4953 4945>,
			<5711 5278 5105 4984 4954 4946>,
			<5759 5291 5114 4988 4957 4947>,
			<5740 5305 5128 4993 4959 4950>,
			<5651 5320 5148 5001 4963 4952>,
			<5587 5326 5156 5010 4968 4957>,
			<5565 5288 5137 5025 4979 4966>,
			<5550 5232 5108 5035 4988 4974>,
			<5535 5205 5087 5022 4981 4969>,
			<5519 5189 5068 4989 4958 4950>,
			<5508 5180 5058 4973 4947 4940>,
			<5501 5175 5055 4969 4946 4940>,
			<5497 5172 5053 4966 4946 4940>,
			<5494 5171 5053 4967 4946 4940>,
			<5490 5172 5054 4967 4947 4941>,
			<5488 5173 5056 4968 4948 4942>,
			<5497 5173 5057 4971 4949 4943>,
			<5520 5173 5058 4975 4950 4944>,
			<5546 5173 5060 4978 4953 4946>,
			<5576 5173 5061 4981 4956 4948>,
			<5611 5172 5062 4982 4958 4949>,
			<5653 5176 5062 4982 4956 4948>,
			<5701 5188 5060 4982 4951 4944>,
			<5757 5202 5059 4979 4949 4942>,
			<5820 5219 5058 4971 4947 4941>,
			<5892 5240 5058 4967 4946 4940>,
			<5971 5262 5059 4967 4946 4940>,
			<6058 5287 5064 4967 4946 4941>,
			<6156 5317 5070 4967 4946 4941>,
			<6263 5353 5081 4968 4946 4942>,
			<6394 5399 5095 4968 4945 4942>,
			<6576 5464 5115 4968 4945 4941>,
			<6840 5566 5148 4973 4949 4944>,
			<6997 5618 5162 4977 4951 4950>,
			<7095 5639 5169 4982 4955 4953>,
			<7310 5720 5192 4987 4957 4948>,
			<7611 5802 5205 4983 4952 4944>,
			<7979 5915 5220 4978 4951 4949>,
			<8995 6145 5278 4988 4955 4950>,
			<11418 6599 5375 4996 4963 4954>,
			<17731 8204 5595 5021 5003 4998>,
			<17731 8204 5595 5021 5003 4998>,
			<17731 8204 5595 5021 5003 4998>;
	};

};
